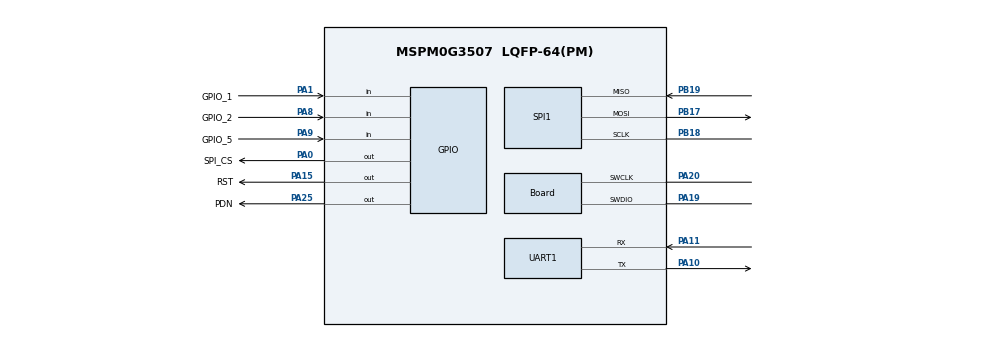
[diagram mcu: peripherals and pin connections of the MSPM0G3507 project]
//@cliArgs --device "MSPM0G350X" --package "LQFP-64(PM)" --part "Default"
//@v2CliArgs --device "MSPM0G3507" --package "LQFP-64(PM)"
// @cliArgs --board /ti/boards/LP_MSPM0G3507 --rtos nortos

/**
 * Import the modules used in this configuration.
 */
const GPIO          = scripting.addModule("/ti/driverlib/GPIO", {}, false);
const GPIO1         = GPIO.addInstance();
const SPI           = scripting.addModule("/ti/driverlib/SPI", {}, false);
const SPI1          = SPI.addInstance();
const SYSCTL        = scripting.addModule("/ti/driverlib/SYSCTL");
const UART          = scripting.addModule("/ti/driverlib/UART", {}, false);
const UART1         = UART.addInstance();
const ProjectConfig = scripting.addModule("/ti/project_config/ProjectConfig");

/**
 * Write custom configuration values to the imported modules.
 */
GPIO1.$name                              = "AFE";
GPIO1.associatedPins.create(6);
GPIO1.associatedPins[0].initialValue     = "SET";
GPIO1.associatedPins[0].$name            = "SPI_CS";
GPIO1.associatedPins[0].pin.$assign      = "PA0";
GPIO1.associatedPins[1].$name            = "RST";
GPIO1.associatedPins[1].initialValue     = "SET";
GPIO1.associatedPins[1].pin.$assign      = "PA15";
GPIO1.associatedPins[2].$name            = "GPIO_1";
GPIO1.associatedPins[2].direction        = "INPUT";
GPIO1.associatedPins[2].pin.$assign      = "PA1";
GPIO1.associatedPins[3].$name            = "GPIO_2";
GPIO1.associatedPins[3].internalResistor = "PULL_DOWN";
GPIO1.associatedPins[3].direction        = "INPUT";
GPIO1.associatedPins[3].interruptEn      = true;
GPIO1.associatedPins[3].polarity         = "RISE";
GPIO1.associatedPins[3].pin.$assign      = "PA8";
GPIO1.associatedPins[4].$name            = "GPIO_5";
GPIO1.associatedPins[4].direction        = "INPUT";
GPIO1.associatedPins[4].pin.$assign      = "PA9";
GPIO1.associatedPins[5].$name            = "PDN";
GPIO1.associatedPins[5].pin.$assign      = "PA25";

const Board = scripting.addModule("/ti/driverlib/Board", {}, false);
Board.peripheral.$assign          = "DEBUGSS";
Board.peripheral.swclkPin.$assign = "PA20";
Board.peripheral.swdioPin.$assign = "PA19";

SPI1.rxFifoThreshold                       = "DL_SPI_RX_FIFO_LEVEL_ONE_FRAME";
SPI1.txFifoThreshold                       = "DL_SPI_TX_FIFO_LEVEL_ONE_FRAME";
SPI1.enabledDMAEvent1Triggers              = "DL_SPI_DMA_INTERRUPT_RX";
SPI1.frameFormat                           = "MOTO3";
SPI1.enabledDMAEvent2Triggers              = "DL_SPI_DMA_INTERRUPT_TX";
SPI1.$name                                 = "AFE_SPI";
SPI1.enabledInterrupts                     = ["DMA_DONE_RX","DMA_DONE_TX","TX_EMPTY"];
SPI1.DMA_CHANNEL_EVENT1.addressMode        = "f2b";
SPI1.DMA_CHANNEL_EVENT1.srcLength          = "BYTE";
SPI1.DMA_CHANNEL_EVENT1.dstLength          = "BYTE";
SPI1.DMA_CHANNEL_EVENT1.$name              = "DMA_SPI_RX";
SPI1.DMA_CHANNEL_EVENT1.peripheral.$assign = "DMA_CH2";
SPI1.peripheral.$assign                    = "SPI0";
SPI1.peripheral.sclkPin.$assign            = "PB18";
SPI1.peripheral.mosiPin.$assign            = "PB17";
SPI1.peripheral.misoPin.$assign            = "PB19";
SPI1.DMA_CHANNEL_EVENT2.srcLength          = "BYTE";
SPI1.DMA_CHANNEL_EVENT2.dstLength          = "BYTE";
SPI1.DMA_CHANNEL_EVENT2.addressMode        = "b2f";
SPI1.DMA_CHANNEL_EVENT2.$name              = "DMA_SPI_TX";
SPI1.DMA_CHANNEL_EVENT2.peripheral.$assign = "DMA_CH3";

SYSCTL.validateClkStatus  = true;
SYSCTL.MCLKSource         = "HSCLK";
SYSCTL.SYSPLL_CLK0En      = true;
SYSCTL.peripheral.$assign = "SYSCTL";

UART1.$name                             = "UART_DAP";
UART1.targetBaudRate                    = 115200;
UART1.enabledDMARXTriggers              = "DL_UART_DMA_INTERRUPT_RX";
UART1.enabledDMATXTriggers              = "DL_UART_DMA_INTERRUPT_TX";
UART1.peripheral.$assign                = "UART0";
UART1.peripheral.rxPin.$assign          = "PA11";
UART1.peripheral.txPin.$assign          = "PA10";
UART1.DMA_CHANNEL_RX.$name              = "DMA_CH0";
UART1.DMA_CHANNEL_RX.addressMode        = "f2b";
UART1.DMA_CHANNEL_RX.srcLength          = "BYTE";
UART1.DMA_CHANNEL_RX.dstLength          = "BYTE";
UART1.DMA_CHANNEL_RX.enableInterrupt    = true;
UART1.DMA_CHANNEL_RX.peripheral.$assign = "DMA_CH1";
UART1.DMA_CHANNEL_TX.$name              = "DMA_CH1";
UART1.DMA_CHANNEL_TX.addressMode        = "b2f";
UART1.DMA_CHANNEL_TX.srcLength          = "BYTE";
UART1.DMA_CHANNEL_TX.dstLength          = "BYTE";
UART1.DMA_CHANNEL_TX.enableInterrupt    = true;
UART1.DMA_CHANNEL_TX.peripheral.$assign = "DMA_CH0";

ProjectConfig.migrationCondition = true;
